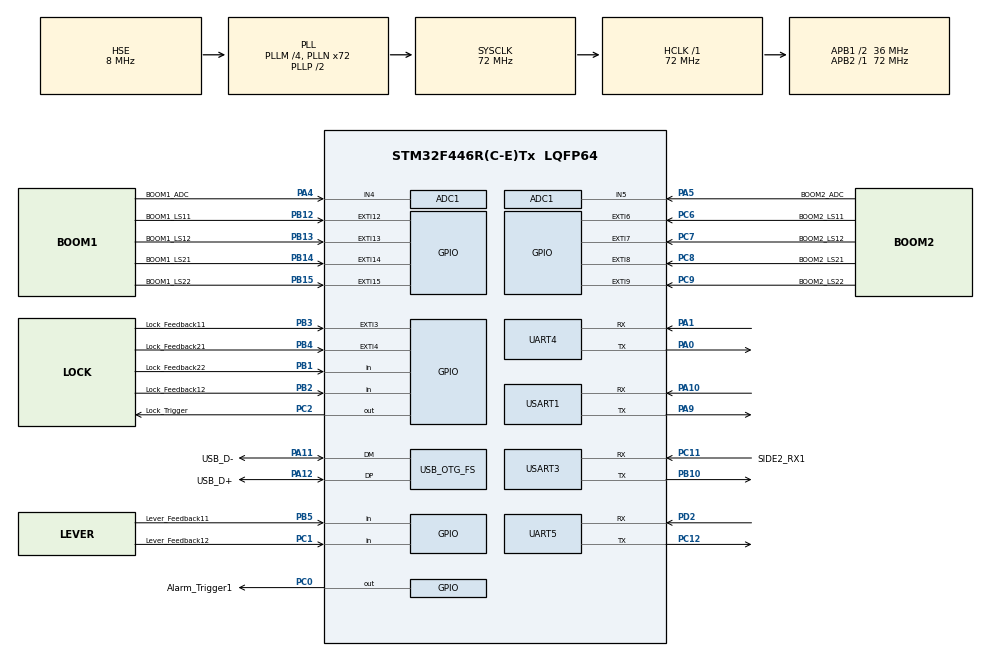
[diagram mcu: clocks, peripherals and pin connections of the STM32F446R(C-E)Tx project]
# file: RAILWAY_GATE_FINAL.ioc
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ADC1.Channel-0\#ChannelRegularConversion=ADC_CHANNEL_4
ADC1.NbrOfConversionFlag=1
ADC1.Rank-0\#ChannelRegularConversion=1
ADC1.SamplingTime-0\#ChannelRegularConversion=ADC_SAMPLETIME_3CYCLES
ADC1.master=1
Mcu.Family=STM32F4
Mcu.Name=STM32F446R(C-E)Tx
Mcu.Package=LQFP64
NVIC.EXTI15_10_IRQn=true\:0\:1\:false\:false\:true\:true\:true\:true
NVIC.EXTI3_IRQn=true\:0\:0\:false\:false\:true\:true\:true\:true
NVIC.EXTI4_IRQn=true\:0\:0\:false\:false\:true\:true\:true\:true
NVIC.EXTI9_5_IRQn=true\:0\:1\:false\:false\:true\:true\:true\:true
NVIC.OTG_FS_IRQn=true\:0\:0\:false\:false\:true\:false\:true\:true
NVIC.PriorityGroup=NVIC_PRIORITYGROUP_0
NVIC.TIM1_UP_TIM10_IRQn=true\:0\:1\:false\:false\:true\:true\:true\:true
PA0-WKUP.Mode=Asynchronous
PA0-WKUP.Signal=UART4_TX
PA1.Mode=Asynchronous
PA1.Signal=UART4_RX
PA10.Mode=Asynchronous
PA10.Signal=USART1_RX
PA11.GPIO_Label=USB_D-
PA11.Mode=Device_Only
PA11.Signal=USB_OTG_FS_DM
PA12.GPIO_Label=USB_D+
PA12.Mode=Device_Only
PA12.Signal=USB_OTG_FS_DP
PA13.Mode=Serial_Wire
PA13.Signal=SYS_JTMS-SWDIO
PA14.Mode=Serial_Wire
PA14.Signal=SYS_JTCK-SWCLK
PA4.GPIO_Label=BOOM1_ADC
PA4.Signal=ADCx_IN4
PA5.GPIO_Label=BOOM2_ADC
PA5.Signal=ADCx_IN5
PA9.Mode=Asynchronous
PA9.Signal=USART1_TX
PB1.GPIO_Label=Lock_Feedback22
PB1.GPIO_PuPd=GPIO_PULLUP
PB1.Signal=GPIO_Input
PB10.Mode=Asynchronous
PB10.Signal=USART3_TX
PB12.GPIO_Label=BOOM1_LS11
PB12.GPIO_ModeDefaultEXTI=GPIO_MODE_IT_RISING_FALLING
PB12.GPIO_PuPd=GPIO_PULLUP
PB12.Signal=GPXTI12
PB13.GPIO_Label=BOOM1_LS12
PB13.GPIO_ModeDefaultEXTI=GPIO_MODE_IT_RISING_FALLING
PB13.GPIO_PuPd=GPIO_PULLUP
PB13.Signal=GPXTI13
PB14.GPIO_Label=BOOM1_LS21
PB14.GPIO_ModeDefaultEXTI=GPIO_MODE_IT_RISING_FALLING
PB14.GPIO_PuPd=GPIO_PULLUP
PB14.Signal=GPXTI14
PB15.GPIO_Label=BOOM1_LS22
PB15.GPIO_ModeDefaultEXTI=GPIO_MODE_IT_RISING_FALLING
PB15.GPIO_PuPd=GPIO_PULLUP
PB15.Signal=GPXTI15
PB2.GPIO_Label=Lock_Feedback12
PB2.GPIO_PuPd=GPIO_PULLUP
PB2.Signal=GPIO_Input
PB3.GPIO_Label=Lock_Feedback11
PB3.GPIO_ModeDefaultEXTI=GPIO_MODE_IT_RISING_FALLING
PB3.GPIO_PuPd=GPIO_PULLUP
PB3.Signal=GPXTI3
PB4.GPIO_Label=Lock_Feedback21
PB4.GPIO_ModeDefaultEXTI=GPIO_MODE_IT_RISING_FALLING
PB4.GPIO_PuPd=GPIO_PULLUP
PB4.Signal=GPXTI4
PB5.GPIO_Label=Lever_Feedback11
PB5.GPIO_PuPd=GPIO_PULLUP
PB5.Signal=GPIO_Input
PC0.GPIO_Label=Alarm_Trigger1
PC0.GPIO_ModeDefaultOutputPP=GPIO_MODE_OUTPUT_OD
PC0.GPIO_PuPd=GPIO_PULLUP
PC0.GPIO_Speed=GPIO_SPEED_FREQ_MEDIUM
PC0.PinState=GPIO_PIN_SET
PC0.Signal=GPIO_Output
PC1.GPIO_Label=Lever_Feedback12
PC1.GPIO_PuPd=GPIO_PULLUP
PC1.Signal=GPIO_Input
PC11.GPIO_Label=SIDE2_RX1
PC11.Mode=Asynchronous
PC11.Signal=USART3_RX
PC12.Mode=Asynchronous
PC12.Signal=UART5_TX
PC2.GPIO_Label=Lock_Trigger
PC2.GPIO_ModeDefaultOutputPP=GPIO_MODE_OUTPUT_OD
PC2.GPIO_PuPd=GPIO_PULLUP
PC2.GPIO_Speed=GPIO_SPEED_FREQ_MEDIUM
PC2.PinState=GPIO_PIN_SET
PC2.Signal=GPIO_Output
PC6.GPIO_Label=BOOM2_LS11
PC6.GPIO_ModeDefaultEXTI=GPIO_MODE_IT_RISING_FALLING
PC6.GPIO_PuPd=GPIO_PULLUP
PC6.Signal=GPXTI6
PC7.GPIO_Label=BOOM2_LS12
PC7.GPIO_ModeDefaultEXTI=GPIO_MODE_IT_RISING_FALLING
PC7.GPIO_PuPd=GPIO_PULLUP
PC7.Signal=GPXTI7
PC8.GPIO_Label=BOOM2_LS21
PC8.GPIO_ModeDefaultEXTI=GPIO_MODE_IT_RISING_FALLING
PC8.GPIO_PuPd=GPIO_PULLUP
PC8.Signal=GPXTI8
PC9.GPIO_Label=BOOM2_LS22
PC9.GPIO_ModeDefaultEXTI=GPIO_MODE_IT_RISING_FALLING
PC9.GPIO_PuPd=GPIO_PULLUP
PC9.Signal=GPXTI9
PD2.Mode=Asynchronous
PD2.Signal=UART5_RX
PH0-OSC_IN.Mode=HSE-External-Oscillator
PH0-OSC_IN.Signal=RCC_OSC_IN
PH1-OSC_OUT.Mode=HSE-External-Oscillator
PH1-OSC_OUT.Signal=RCC_OSC_OUT
ProjectManager.HeapSize=0x200
ProjectManager.StackSize=0x400
ProjectManager.TargetToolchain=STM32CubeIDE
RCC.AHBFreq_Value=72000000
RCC.APB1CLKDivider=RCC_HCLK_DIV2
RCC.APB1Freq_Value=36000000
RCC.APB1TimFreq_Value=72000000
RCC.APB2Freq_Value=72000000
RCC.APB2TimFreq_Value=72000000
RCC.CortexFreq_Value=72000000
RCC.FLatency-AdvancedSettings=FLASH_LATENCY_2
RCC.HCLKFreq_Value=72000000
RCC.HSE_VALUE=8000000
RCC.HSI_VALUE=16000000
RCC.PLLM=4
RCC.PLLN=72
RCC.PLLQ=3
RCC.SYSCLKFreq_VALUE=72000000
RCC.SYSCLKSource=RCC_SYSCLKSOURCE_PLLCLK
RCC.USBFreq_Value=48000000
RCC.VCOOutputFreq_Value=144000000
SH.ADCx_IN4.0=ADC1_IN4,IN4
SH.ADCx_IN5.0=ADC1_IN5,IN5
TIM1.Period=65535
TIM1.Prescaler=16467
UART4.VirtualMode=Asynchronous
UART5.VirtualMode=Asynchronous
USART1.VirtualMode=VM_ASYNC
USART3.VirtualMode=VM_ASYNC
USB_DEVICE.CLASS_NAME_FS=CDC
USB_DEVICE.MANUFACTURER_STRING-CDC_FS=HesperTech PVT Ltd\:
USB_DEVICE.PRODUCT_STRING_CDC_FS=HESPER TECH VCP
USB_DEVICE.VirtualMode-CDC_FS=Cdc
USB_DEVICE.VirtualModeFS=Cdc_FS
USB_OTG_FS.VirtualMode=Device_Only
VP_TIM1_VS_ClockSourceINT.Mode=Internal
VP_TIM1_VS_ClockSourceITR.Mode=TriggerSource_ITR0
VP_USB_DEVICE_VS_USB_DEVICE_CDC_FS.Mode=CDC_FS
board=NUCLEO-F446RE

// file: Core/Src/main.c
/* USER CODE BEGIN Header */
/**
  ******************************************************************************
  * @file           : main.c
  * @brief          : Main program body
  ******************************************************************************
  * @attention
  *
  * Copyright (c) 2025 STMicroelectronics.
  * All rights reserved.
  *
  * This software is licensed under terms that can be found in the LICENSE file
  * in the root directory of this software component.
  * If no LICENSE file comes with this software, it is provided AS-IS.
  *
  ******************************************************************************
  */
/* USER CODE END Header */
#include "main.h"
#include "usb_device.h"

/* USER CODE BEGIN Includes */
#include "POLL.h"
#include "COM.h"
#include "ACT.h"
#include "WRAPPER.h"
/* USER CODE END Includes */

ADC_HandleTypeDef hadc1;

TIM_HandleTypeDef htim1;

UART_HandleTypeDef huart4;
UART_HandleTypeDef huart5;
UART_HandleTypeDef huart1;
UART_HandleTypeDef huart3;

void SystemClock_Config(void);
static void MX_GPIO_Init(void);
static void MX_TIM1_Init(void);
static void MX_USART1_UART_Init(void);
static void MX_USART3_UART_Init(void);
static void MX_UART4_Init(void);
static void MX_ADC1_Init(void);
static void MX_UART5_Init(void);

int main(void)
{

  /* MCU Configuration--------------------------------------------------------*/

  /* Reset of all peripherals, Initializes the Flash interface and the Systick. */
  HAL_Init();

  /* Configure the system clock */
  SystemClock_Config();

  /* Initialize all configured peripherals */
  MX_GPIO_Init();
  MX_TIM1_Init();
  MX_USART1_UART_Init();
  MX_USART3_UART_Init();
  MX_USB_DEVICE_Init();
  MX_UART4_Init();
  MX_ADC1_Init();
  MX_UART5_Init();
  /* USER CODE BEGIN 2 */

  //char buff1[20] = {0};
  //char buff2[20] = {0};

  // Start TIM1 with interrupt
  HAL_TIM_Base_Start_IT(&htim1); /* 15s Interrupt Timer Start */
  /* USER CODE END 2 */

  /* Infinite loop */
  /* USER CODE BEGIN WHILE */
  while (1)
  {
	  Start_Polling();    /* Starts Polling the status of all sensors */
	  Send_If_Change();   /* If any change is detected with the Previous state tx msg is done */
	  Receive_Handler();  /* Used to Trigger lever lock and alarm based on rx data */
	  //Sys_rst(); /* Resets the stm32 every 24Hrs */

//	    uint16_t dist1 = TF02_Get_Dist(&huart3);
//      uint16_t dist2 = TF02_Get_Dist(&huart4);
//
//      sprintf(buff1,"lidar1: %d \r\n",dist1);
//      sprintf(buff2,"lidar2: %d \r\n",dist2);
//      while(1){
//    	  if(CDC_Transmit_FS((uint8_t*)buff1,strlen(buff1)) == USBD_OK) break;
//      }
//      while(1)
//    	  {
//    	  if(CDC_Transmit_FS((uint8_t*)buff2,strlen(buff2)) == USBD_OK) break;
//    	  }
//
//      HAL_Delay(200);

    /* USER CODE END WHILE */

  }
}

void SystemClock_Config(void)
{
  RCC_OscInitTypeDef RCC_OscInitStruct = {0};
  RCC_ClkInitTypeDef RCC_ClkInitStruct = {0};

  /** Configure the main internal regulator output voltage
  */
  __HAL_RCC_PWR_CLK_ENABLE();
  __HAL_PWR_VOLTAGESCALING_CONFIG(PWR_REGULATOR_VOLTAGE_SCALE3);

  /** Initializes the RCC Oscillators according to the specified parameters
  * in the RCC_OscInitTypeDef structure.
  */
  RCC_OscInitStruct.OscillatorType = RCC_OSCILLATORTYPE_HSE;
  RCC_OscInitStruct.HSEState = RCC_HSE_ON;
  RCC_OscInitStruct.PLL.PLLState = RCC_PLL_ON;
  RCC_OscInitStruct.PLL.PLLSource = RCC_PLLSOURCE_HSE;
  RCC_OscInitStruct.PLL.PLLM = 4;
  RCC_OscInitStruct.PLL.PLLN = 72;
  RCC_OscInitStruct.PLL.PLLP = RCC_PLLP_DIV2;
  RCC_OscInitStruct.PLL.PLLQ = 3;
  RCC_OscInitStruct.PLL.PLLR = 2;
  if (HAL_RCC_OscConfig(&RCC_OscInitStruct) != HAL_OK)
  {
    Error_Handler();
  }

  /** Initializes the CPU, AHB and APB buses clocks
  */
  RCC_ClkInitStruct.ClockType = RCC_CLOCKTYPE_HCLK|RCC_CLOCKTYPE_SYSCLK
                              |RCC_CLOCKTYPE_PCLK1|RCC_CLOCKTYPE_PCLK2;
  RCC_ClkInitStruct.SYSCLKSource = RCC_SYSCLKSOURCE_PLLCLK;
  RCC_ClkInitStruct.AHBCLKDivider = RCC_SYSCLK_DIV1;
  RCC_ClkInitStruct.APB1CLKDivider = RCC_HCLK_DIV2;
  RCC_ClkInitStruct.APB2CLKDivider = RCC_HCLK_DIV1;

  if (HAL_RCC_ClockConfig(&RCC_ClkInitStruct, FLASH_LATENCY_2) != HAL_OK)
  {
    Error_Handler();
  }
}

static void MX_ADC1_Init(void)
{

  ADC_ChannelConfTypeDef sConfig = {0};

  /** Configure the global features of the ADC (Clock, Resolution, Data Alignment and number of conversion)
  */
  hadc1.Instance = ADC1;
  hadc1.Init.ClockPrescaler = ADC_CLOCK_SYNC_PCLK_DIV2;
  hadc1.Init.Resolution = ADC_RESOLUTION_12B;
  hadc1.Init.ScanConvMode = DISABLE;
  hadc1.Init.ContinuousConvMode = DISABLE;
  hadc1.Init.DiscontinuousConvMode = DISABLE;
  hadc1.Init.ExternalTrigConvEdge = ADC_EXTERNALTRIGCONVEDGE_NONE;
  hadc1.Init.ExternalTrigConv = ADC_SOFTWARE_START;
  hadc1.Init.DataAlign = ADC_DATAALIGN_RIGHT;
  hadc1.Init.NbrOfConversion = 1;
  hadc1.Init.DMAContinuousRequests = DISABLE;
  hadc1.Init.EOCSelection = ADC_EOC_SINGLE_CONV;
  if (HAL_ADC_Init(&hadc1) != HAL_OK)
  {
    Error_Handler();
  }

  /** Configure for the selected ADC regular channel its corresponding rank in the sequencer and its sample time.
  */
  sConfig.Channel = ADC_CHANNEL_4;
  sConfig.Rank = 1;
  sConfig.SamplingTime = ADC_SAMPLETIME_3CYCLES;
  if (HAL_ADC_ConfigChannel(&hadc1, &sConfig) != HAL_OK)
  {
    Error_Handler();
  }

}

static void MX_TIM1_Init(void)
{

  TIM_ClockConfigTypeDef sClockSourceConfig = {0};
  TIM_SlaveConfigTypeDef sSlaveConfig = {0};
  TIM_MasterConfigTypeDef sMasterConfig = {0};

  htim1.Instance = TIM1;
  htim1.Init.Prescaler = 16467;
  htim1.Init.CounterMode = TIM_COUNTERMODE_UP;
  htim1.Init.Period = 65535;
  htim1.Init.ClockDivision = TIM_CLOCKDIVISION_DIV1;
  htim1.Init.RepetitionCounter = 0;
  htim1.Init.AutoReloadPreload = TIM_AUTORELOAD_PRELOAD_DISABLE;
  if (HAL_TIM_Base_Init(&htim1) != HAL_OK)
  {
    Error_Handler();
  }
  sClockSourceConfig.ClockSource = TIM_CLOCKSOURCE_INTERNAL;
  if (HAL_TIM_ConfigClockSource(&htim1, &sClockSourceConfig) != HAL_OK)
  {
    Error_Handler();
  }
  sSlaveConfig.SlaveMode = TIM_SLAVEMODE_DISABLE;
  sSlaveConfig.InputTrigger = TIM_TS_ITR0;
  if (HAL_TIM_SlaveConfigSynchro(&htim1, &sSlaveConfig) != HAL_OK)
  {
    Error_Handler();
  }
  sMasterConfig.MasterOutputTrigger = TIM_TRGO_RESET;
  sMasterConfig.MasterSlaveMode = TIM_MASTERSLAVEMODE_DISABLE;
  if (HAL_TIMEx_MasterConfigSynchronization(&htim1, &sMasterConfig) != HAL_OK)
  {
    Error_Handler();
  }

}

static void MX_UART4_Init(void)
{

  huart4.Instance = UART4;
  huart4.Init.BaudRate = 115200;
  huart4.Init.WordLength = UART_WORDLENGTH_8B;
  huart4.Init.StopBits = UART_STOPBITS_1;
  huart4.Init.Parity = UART_PARITY_NONE;
  huart4.Init.Mode = UART_MODE_TX_RX;
  huart4.Init.HwFlowCtl = UART_HWCONTROL_NONE;
  huart4.Init.OverSampling = UART_OVERSAMPLING_16;
  if (HAL_UART_Init(&huart4) != HAL_OK)
  {
    Error_Handler();
  }

}

static void MX_UART5_Init(void)
{

  huart5.Instance = UART5;
  huart5.Init.BaudRate = 115200;
  huart5.Init.WordLength = UART_WORDLENGTH_8B;
  huart5.Init.StopBits = UART_STOPBITS_1;
  huart5.Init.Parity = UART_PARITY_NONE;
  huart5.Init.Mode = UART_MODE_TX_RX;
  huart5.Init.HwFlowCtl = UART_HWCONTROL_NONE;
  huart5.Init.OverSampling = UART_OVERSAMPLING_16;
  if (HAL_UART_Init(&huart5) != HAL_OK)
  {
    Error_Handler();
  }

}

static void MX_USART1_UART_Init(void)
{

  huart1.Instance = USART1;
  huart1.Init.BaudRate = 115200;
  huart1.Init.WordLength = UART_WORDLENGTH_8B;
  huart1.Init.StopBits = UART_STOPBITS_1;
  huart1.Init.Parity = UART_PARITY_NONE;
  huart1.Init.Mode = UART_MODE_TX_RX;
  huart1.Init.HwFlowCtl = UART_HWCONTROL_NONE;
  huart1.Init.OverSampling = UART_OVERSAMPLING_16;
  if (HAL_UART_Init(&huart1) != HAL_OK)
  {
    Error_Handler();
  }

}

static void MX_USART3_UART_Init(void)
{

  huart3.Instance = USART3;
  huart3.Init.BaudRate = 115200;
  huart3.Init.WordLength = UART_WORDLENGTH_8B;
  huart3.Init.StopBits = UART_STOPBITS_1;
  huart3.Init.Parity = UART_PARITY_NONE;
  huart3.Init.Mode = UART_MODE_TX_RX;
  huart3.Init.HwFlowCtl = UART_HWCONTROL_NONE;
  huart3.Init.OverSampling = UART_OVERSAMPLING_16;
  if (HAL_UART_Init(&huart3) != HAL_OK)
  {
    Error_Handler();
  }

}

static void MX_GPIO_Init(void)
{
  GPIO_InitTypeDef GPIO_InitStruct = {0};

  /* GPIO Ports Clock Enable */
  __HAL_RCC_GPIOH_CLK_ENABLE();
  __HAL_RCC_GPIOC_CLK_ENABLE();
  __HAL_RCC_GPIOA_CLK_ENABLE();
  __HAL_RCC_GPIOB_CLK_ENABLE();
  __HAL_RCC_GPIOD_CLK_ENABLE();

  /*Configure GPIO pin Output Level */
  HAL_GPIO_WritePin(GPIOC, Alarm_Trigger1_Pin|Lock_Trigger_Pin, GPIO_PIN_SET);

  /*Configure GPIO pins : Alarm_Trigger1_Pin Lock_Trigger_Pin */
  GPIO_InitStruct.Pin = Alarm_Trigger1_Pin|Lock_Trigger_Pin;
  GPIO_InitStruct.Mode = GPIO_MODE_OUTPUT_OD;
  GPIO_InitStruct.Pull = GPIO_PULLUP;
  GPIO_InitStruct.Speed = GPIO_SPEED_FREQ_MEDIUM;
  HAL_GPIO_Init(GPIOC, &GPIO_InitStruct);

  /*Configure GPIO pin : Lever_Feedback12_Pin */
  GPIO_InitStruct.Pin = Lever_Feedback12_Pin;
  GPIO_InitStruct.Mode = GPIO_MODE_INPUT;
  GPIO_InitStruct.Pull = GPIO_PULLUP;
  HAL_GPIO_Init(Lever_Feedback12_GPIO_Port, &GPIO_InitStruct);

  /*Configure GPIO pins : Lock_Feedback22_Pin Lock_Feedback12_Pin Lever_Feedback11_Pin */
  GPIO_InitStruct.Pin = Lock_Feedback22_Pin|Lock_Feedback12_Pin|Lever_Feedback11_Pin;
  GPIO_InitStruct.Mode = GPIO_MODE_INPUT;
  GPIO_InitStruct.Pull = GPIO_PULLUP;
  HAL_GPIO_Init(GPIOB, &GPIO_InitStruct);

  /*Configure GPIO pins : BOOM1_LS11_Pin BOOM1_LS12_Pin BOOM1_LS21_Pin BOOM1_LS22_Pin
                           Lock_Feedback11_Pin Lock_Feedback21_Pin */
  GPIO_InitStruct.Pin = BOOM1_LS11_Pin|BOOM1_LS12_Pin|BOOM1_LS21_Pin|BOOM1_LS22_Pin
                          |Lock_Feedback11_Pin|Lock_Feedback21_Pin;
  GPIO_InitStruct.Mode = GPIO_MODE_IT_RISING_FALLING;
  GPIO_InitStruct.Pull = GPIO_PULLUP;
  HAL_GPIO_Init(GPIOB, &GPIO_InitStruct);

  /*Configure GPIO pins : BOOM2_LS11_Pin BOOM2_LS12_Pin BOOM2_LS21_Pin BOOM2_LS22_Pin */
  GPIO_InitStruct.Pin = BOOM2_LS11_Pin|BOOM2_LS12_Pin|BOOM2_LS21_Pin|BOOM2_LS22_Pin;
  GPIO_InitStruct.Mode = GPIO_MODE_IT_RISING_FALLING;
  GPIO_InitStruct.Pull = GPIO_PULLUP;
  HAL_GPIO_Init(GPIOC, &GPIO_InitStruct);

  /* EXTI interrupt init*/
  HAL_NVIC_SetPriority(EXTI3_IRQn, 0, 0);
  HAL_NVIC_EnableIRQ(EXTI3_IRQn);

  HAL_NVIC_SetPriority(EXTI4_IRQn, 0, 0);
  HAL_NVIC_EnableIRQ(EXTI4_IRQn);

  HAL_NVIC_SetPriority(EXTI9_5_IRQn, 0, 1);
  HAL_NVIC_EnableIRQ(EXTI9_5_IRQn);

  HAL_NVIC_SetPriority(EXTI15_10_IRQn, 0, 1);
  HAL_NVIC_EnableIRQ(EXTI15_10_IRQn);

}

void Error_Handler(void)
{
  __disable_irq();
  while (1)
  {
  }
}
